# ESP32-S31 register map
Vendor: ESPRESSIF SYSTEMS (SHANGHAI) CO., LTD.; Series: ESP32 S-Series; File version: 1
CPU: RV32IMAFC r0p0, little endian, no MPU, FPU, 0 interrupt priority bits
Address unit: 32 bits
Registers are 32-bit, read-write, reset 0x0 unless marked. A register's access mark holds for its fields unless they carry their own. Offsets are from the block's base; [hi:lo] are bit positions; {n}, {i} and the like mark numbered series.

## SOC_ETM (part 2 of 4) — Event Task Matrix
Base 0x20393000
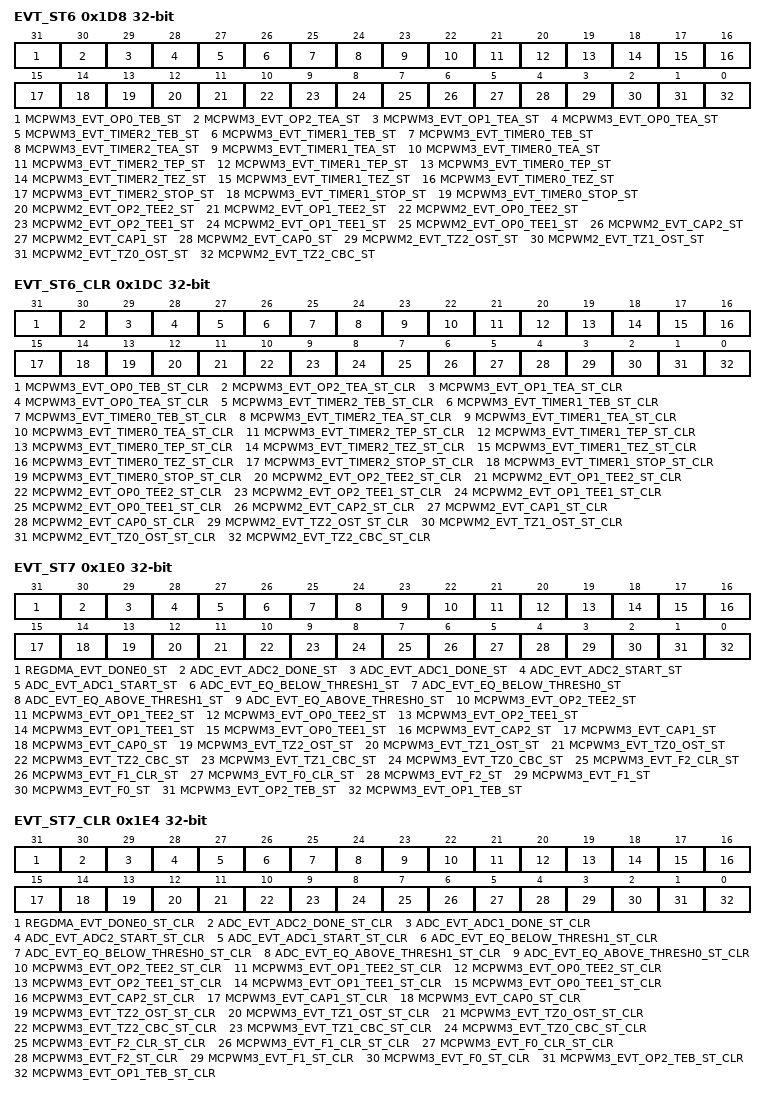
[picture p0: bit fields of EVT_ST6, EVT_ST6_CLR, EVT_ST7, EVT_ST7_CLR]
0x1D8 EVT_ST6 — Events trigger status register
  [31] MCPWM3_EVT_OP0_TEB_ST — Represents MCPWM3_evt_op0_teb trigger status.\\0: Not triggered\\1: Triggered
  [30] MCPWM3_EVT_OP2_TEA_ST — Represents MCPWM3_evt_op2_tea trigger status.\\0: Not triggered\\1: Triggered
  [29] MCPWM3_EVT_OP1_TEA_ST — Represents MCPWM3_evt_op1_tea trigger status.\\0: Not triggered\\1: Triggered
  [28] MCPWM3_EVT_OP0_TEA_ST — Represents MCPWM3_evt_op0_tea trigger status.\\0: Not triggered\\1: Triggered
  [27] MCPWM3_EVT_TIMER2_TEB_ST — Represents MCPWM3_evt_timer2_teb trigger status.\\0: Not triggered\\1: Triggered
  [26] MCPWM3_EVT_TIMER1_TEB_ST — Represents MCPWM3_evt_timer1_teb trigger status.\\0: Not triggered\\1: Triggered
  [25] MCPWM3_EVT_TIMER0_TEB_ST — Represents MCPWM3_evt_timer0_teb trigger status.\\0: Not triggered\\1: Triggered
  [24] MCPWM3_EVT_TIMER2_TEA_ST — Represents MCPWM3_evt_timer2_tea trigger status.\\0: Not triggered\\1: Triggered
  [23] MCPWM3_EVT_TIMER1_TEA_ST — Represents MCPWM3_evt_timer1_tea trigger status.\\0: Not triggered\\1: Triggered
  [22] MCPWM3_EVT_TIMER0_TEA_ST — Represents MCPWM3_evt_timer0_tea trigger status.\\0: Not triggered\\1: Triggered
  [21] MCPWM3_EVT_TIMER2_TEP_ST — Represents MCPWM3_evt_timer2_tep trigger status.\\0: Not triggered\\1: Triggered
  [20] MCPWM3_EVT_TIMER1_TEP_ST — Represents MCPWM3_evt_timer1_tep trigger status.\\0: Not triggered\\1: Triggered
  [19] MCPWM3_EVT_TIMER0_TEP_ST — Represents MCPWM3_evt_timer0_tep trigger status.\\0: Not triggered\\1: Triggered
  [18] MCPWM3_EVT_TIMER2_TEZ_ST — Represents MCPWM3_evt_timer2_tez trigger status.\\0: Not triggered\\1: Triggered
  [17] MCPWM3_EVT_TIMER1_TEZ_ST — Represents MCPWM3_evt_timer1_tez trigger status.\\0: Not triggered\\1: Triggered
  [16] MCPWM3_EVT_TIMER0_TEZ_ST — Represents MCPWM3_evt_timer0_tez trigger status.\\0: Not triggered\\1: Triggered
  [15] MCPWM3_EVT_TIMER2_STOP_ST — Represents MCPWM3_evt_timer2_stop trigger status.\\0: Not triggered\\1: Triggered
  [14] MCPWM3_EVT_TIMER1_STOP_ST — Represents MCPWM3_evt_timer1_stop trigger status.\\0: Not triggered\\1: Triggered
  [13] MCPWM3_EVT_TIMER0_STOP_ST — Represents MCPWM3_evt_timer0_stop trigger status.\\0: Not triggered\\1: Triggered
  [12] MCPWM2_EVT_OP2_TEE2_ST — Represents MCPWM2_evt_op2_tee2 trigger status.\\0: Not triggered\\1: Triggered
  [11] MCPWM2_EVT_OP1_TEE2_ST — Represents MCPWM2_evt_op1_tee2 trigger status.\\0: Not triggered\\1: Triggered
  [10] MCPWM2_EVT_OP0_TEE2_ST — Represents MCPWM2_evt_op0_tee2 trigger status.\\0: Not triggered\\1: Triggered
  [9] MCPWM2_EVT_OP2_TEE1_ST — Represents MCPWM2_evt_op2_tee1 trigger status.\\0: Not triggered\\1: Triggered
  [8] MCPWM2_EVT_OP1_TEE1_ST — Represents MCPWM2_evt_op1_tee1 trigger status.\\0: Not triggered\\1: Triggered
  [7] MCPWM2_EVT_OP0_TEE1_ST — Represents MCPWM2_evt_op0_tee1 trigger status.\\0: Not triggered\\1: Triggered
  [6] MCPWM2_EVT_CAP2_ST — Represents MCPWM2_evt_cap2 trigger status.\\0: Not triggered\\1: Triggered
  [5] MCPWM2_EVT_CAP1_ST — Represents MCPWM2_evt_cap1 trigger status.\\0: Not triggered\\1: Triggered
  [4] MCPWM2_EVT_CAP0_ST — Represents MCPWM2_evt_cap0 trigger status.\\0: Not triggered\\1: Triggered
  [3] MCPWM2_EVT_TZ2_OST_ST — Represents MCPWM2_evt_tz2_ost trigger status.\\0: Not triggered\\1: Triggered
  [2] MCPWM2_EVT_TZ1_OST_ST — Represents MCPWM2_evt_tz1_ost trigger status.\\0: Not triggered\\1: Triggered
  [1] MCPWM2_EVT_TZ0_OST_ST — Represents MCPWM2_evt_tz0_ost trigger status.\\0: Not triggered\\1: Triggered
  [0] MCPWM2_EVT_TZ2_CBC_ST — Represents MCPWM2_evt_tz2_cbc trigger status.\\0: Not triggered\\1: Triggered
0x1DC EVT_ST6_CLR wo — Events trigger status clear register
  [31] MCPWM3_EVT_OP0_TEB_ST_CLR — Configures whether or not to clear MCPWM3_evt_op0_teb trigger status.\\0: Invalid, No effect\\1: Clear
  [30] MCPWM3_EVT_OP2_TEA_ST_CLR — Configures whether or not to clear MCPWM3_evt_op2_tea trigger status.\\0: Invalid, No effect\\1: Clear
  [29] MCPWM3_EVT_OP1_TEA_ST_CLR — Configures whether or not to clear MCPWM3_evt_op1_tea trigger status.\\0: Invalid, No effect\\1: Clear
  [28] MCPWM3_EVT_OP0_TEA_ST_CLR — Configures whether or not to clear MCPWM3_evt_op0_tea trigger status.\\0: Invalid, No effect\\1: Clear
  [27] MCPWM3_EVT_TIMER2_TEB_ST_CLR — Configures whether or not to clear MCPWM3_evt_timer2_teb trigger status.\\0: Invalid, No effect\\1: Clear
  [26] MCPWM3_EVT_TIMER1_TEB_ST_CLR — Configures whether or not to clear MCPWM3_evt_timer1_teb trigger status.\\0: Invalid, No effect\\1: Clear
  [25] MCPWM3_EVT_TIMER0_TEB_ST_CLR — Configures whether or not to clear MCPWM3_evt_timer0_teb trigger status.\\0: Invalid, No effect\\1: Clear
  [24] MCPWM3_EVT_TIMER2_TEA_ST_CLR — Configures whether or not to clear MCPWM3_evt_timer2_tea trigger status.\\0: Invalid, No effect\\1: Clear
  [23] MCPWM3_EVT_TIMER1_TEA_ST_CLR — Configures whether or not to clear MCPWM3_evt_timer1_tea trigger status.\\0: Invalid, No effect\\1: Clear
  [22] MCPWM3_EVT_TIMER0_TEA_ST_CLR — Configures whether or not to clear MCPWM3_evt_timer0_tea trigger status.\\0: Invalid, No effect\\1: Clear
  [21] MCPWM3_EVT_TIMER2_TEP_ST_CLR — Configures whether or not to clear MCPWM3_evt_timer2_tep trigger status.\\0: Invalid, No effect\\1: Clear
  [20] MCPWM3_EVT_TIMER1_TEP_ST_CLR — Configures whether or not to clear MCPWM3_evt_timer1_tep trigger status.\\0: Invalid, No effect\\1: Clear
  [19] MCPWM3_EVT_TIMER0_TEP_ST_CLR — Configures whether or not to clear MCPWM3_evt_timer0_tep trigger status.\\0: Invalid, No effect\\1: Clear
  [18] MCPWM3_EVT_TIMER2_TEZ_ST_CLR — Configures whether or not to clear MCPWM3_evt_timer2_tez trigger status.\\0: Invalid, No effect\\1: Clear
  [17] MCPWM3_EVT_TIMER1_TEZ_ST_CLR — Configures whether or not to clear MCPWM3_evt_timer1_tez trigger status.\\0: Invalid, No effect\\1: Clear
  [16] MCPWM3_EVT_TIMER0_TEZ_ST_CLR — Configures whether or not to clear MCPWM3_evt_timer0_tez trigger status.\\0: Invalid, No effect\\1: Clear
  [15] MCPWM3_EVT_TIMER2_STOP_ST_CLR — Configures whether or not to clear MCPWM3_evt_timer2_stop trigger status.\\0: Invalid, No effect\\1: Clear
  [14] MCPWM3_EVT_TIMER1_STOP_ST_CLR — Configures whether or not to clear MCPWM3_evt_timer1_stop trigger status.\\0: Invalid, No effect\\1: Clear
  [13] MCPWM3_EVT_TIMER0_STOP_ST_CLR — Configures whether or not to clear MCPWM3_evt_timer0_stop trigger status.\\0: Invalid, No effect\\1: Clear
  [12] MCPWM2_EVT_OP2_TEE2_ST_CLR — Configures whether or not to clear MCPWM2_evt_op2_tee2 trigger status.\\0: Invalid, No effect\\1: Clear
  [11] MCPWM2_EVT_OP1_TEE2_ST_CLR — Configures whether or not to clear MCPWM2_evt_op1_tee2 trigger status.\\0: Invalid, No effect\\1: Clear
  [10] MCPWM2_EVT_OP0_TEE2_ST_CLR — Configures whether or not to clear MCPWM2_evt_op0_tee2 trigger status.\\0: Invalid, No effect\\1: Clear
  [9] MCPWM2_EVT_OP2_TEE1_ST_CLR — Configures whether or not to clear MCPWM2_evt_op2_tee1 trigger status.\\0: Invalid, No effect\\1: Clear
  [8] MCPWM2_EVT_OP1_TEE1_ST_CLR — Configures whether or not to clear MCPWM2_evt_op1_tee1 trigger status.\\0: Invalid, No effect\\1: Clear
  [7] MCPWM2_EVT_OP0_TEE1_ST_CLR — Configures whether or not to clear MCPWM2_evt_op0_tee1 trigger status.\\0: Invalid, No effect\\1: Clear
  [6] MCPWM2_EVT_CAP2_ST_CLR — Configures whether or not to clear MCPWM2_evt_cap2 trigger status.\\0: Invalid, No effect\\1: Clear
  [5] MCPWM2_EVT_CAP1_ST_CLR — Configures whether or not to clear MCPWM2_evt_cap1 trigger status.\\0: Invalid, No effect\\1: Clear
  [4] MCPWM2_EVT_CAP0_ST_CLR — Configures whether or not to clear MCPWM2_evt_cap0 trigger status.\\0: Invalid, No effect\\1: Clear
  [3] MCPWM2_EVT_TZ2_OST_ST_CLR — Configures whether or not to clear MCPWM2_evt_tz2_ost trigger status.\\0: Invalid, No effect\\1: Clear
  [2] MCPWM2_EVT_TZ1_OST_ST_CLR — Configures whether or not to clear MCPWM2_evt_tz1_ost trigger status.\\0: Invalid, No effect\\1: Clear
  [1] MCPWM2_EVT_TZ0_OST_ST_CLR — Configures whether or not to clear MCPWM2_evt_tz0_ost trigger status.\\0: Invalid, No effect\\1: Clear
  [0] MCPWM2_EVT_TZ2_CBC_ST_CLR — Configures whether or not to clear MCPWM2_evt_tz2_cbc trigger status.\\0: Invalid, No effect\\1: Clear
0x1E0 EVT_ST7 — Events trigger status register
  [31] REGDMA_EVT_DONE0_ST — Represents REGDMA_evt_done0 trigger status.\\0: Not triggered\\1: Triggered
  [30] ADC_EVT_ADC2_DONE_ST — Represents ADC_evt_adc2_done trigger status.\\0: Not triggered\\1: Triggered
  [29] ADC_EVT_ADC1_DONE_ST — Represents ADC_evt_adc1_done trigger status.\\0: Not triggered\\1: Triggered
  [28] ADC_EVT_ADC2_START_ST — Represents ADC_evt_adc2_start trigger status.\\0: Not triggered\\1: Triggered
  [27] ADC_EVT_ADC1_START_ST — Represents ADC_evt_adc1_start trigger status.\\0: Not triggered\\1: Triggered
  [26] ADC_EVT_EQ_BELOW_THRESH1_ST — Represents ADC_evt_eq_below_thresh1 trigger status.\\0: Not triggered\\1: Triggered
  [25] ADC_EVT_EQ_BELOW_THRESH0_ST — Represents ADC_evt_eq_below_thresh0 trigger status.\\0: Not triggered\\1: Triggered
  [24] ADC_EVT_EQ_ABOVE_THRESH1_ST — Represents ADC_evt_eq_above_thresh1 trigger status.\\0: Not triggered\\1: Triggered
  [23] ADC_EVT_EQ_ABOVE_THRESH0_ST — Represents ADC_evt_eq_above_thresh0 trigger status.\\0: Not triggered\\1: Triggered
  [22] MCPWM3_EVT_OP2_TEE2_ST — Represents MCPWM3_evt_op2_tee2 trigger status.\\0: Not triggered\\1: Triggered
  [21] MCPWM3_EVT_OP1_TEE2_ST — Represents MCPWM3_evt_op1_tee2 trigger status.\\0: Not triggered\\1: Triggered
  [20] MCPWM3_EVT_OP0_TEE2_ST — Represents MCPWM3_evt_op0_tee2 trigger status.\\0: Not triggered\\1: Triggered
  [19] MCPWM3_EVT_OP2_TEE1_ST — Represents MCPWM3_evt_op2_tee1 trigger status.\\0: Not triggered\\1: Triggered
  [18] MCPWM3_EVT_OP1_TEE1_ST — Represents MCPWM3_evt_op1_tee1 trigger status.\\0: Not triggered\\1: Triggered
  [17] MCPWM3_EVT_OP0_TEE1_ST — Represents MCPWM3_evt_op0_tee1 trigger status.\\0: Not triggered\\1: Triggered
  [16] MCPWM3_EVT_CAP2_ST — Represents MCPWM3_evt_cap2 trigger status.\\0: Not triggered\\1: Triggered
  [15] MCPWM3_EVT_CAP1_ST — Represents MCPWM3_evt_cap1 trigger status.\\0: Not triggered\\1: Triggered
  [14] MCPWM3_EVT_CAP0_ST — Represents MCPWM3_evt_cap0 trigger status.\\0: Not triggered\\1: Triggered
  [13] MCPWM3_EVT_TZ2_OST_ST — Represents MCPWM3_evt_tz2_ost trigger status.\\0: Not triggered\\1: Triggered
  [12] MCPWM3_EVT_TZ1_OST_ST — Represents MCPWM3_evt_tz1_ost trigger status.\\0: Not triggered\\1: Triggered
  [11] MCPWM3_EVT_TZ0_OST_ST — Represents MCPWM3_evt_tz0_ost trigger status.\\0: Not triggered\\1: Triggered
  [10] MCPWM3_EVT_TZ2_CBC_ST — Represents MCPWM3_evt_tz2_cbc trigger status.\\0: Not triggered\\1: Triggered
  [9] MCPWM3_EVT_TZ1_CBC_ST — Represents MCPWM3_evt_tz1_cbc trigger status.\\0: Not triggered\\1: Triggered
  [8] MCPWM3_EVT_TZ0_CBC_ST — Represents MCPWM3_evt_tz0_cbc trigger status.\\0: Not triggered\\1: Triggered
  [7] MCPWM3_EVT_F2_CLR_ST — Represents MCPWM3_evt_f2_clr trigger status.\\0: Not triggered\\1: Triggered
  [6] MCPWM3_EVT_F1_CLR_ST — Represents MCPWM3_evt_f1_clr trigger status.\\0: Not triggered\\1: Triggered
  [5] MCPWM3_EVT_F0_CLR_ST — Represents MCPWM3_evt_f0_clr trigger status.\\0: Not triggered\\1: Triggered
  [4] MCPWM3_EVT_F2_ST — Represents MCPWM3_evt_f2 trigger status.\\0: Not triggered\\1: Triggered
  [3] MCPWM3_EVT_F1_ST — Represents MCPWM3_evt_f1 trigger status.\\0: Not triggered\\1: Triggered
  [2] MCPWM3_EVT_F0_ST — Represents MCPWM3_evt_f0 trigger status.\\0: Not triggered\\1: Triggered
  [1] MCPWM3_EVT_OP2_TEB_ST — Represents MCPWM3_evt_op2_teb trigger status.\\0: Not triggered\\1: Triggered
  [0] MCPWM3_EVT_OP1_TEB_ST — Represents MCPWM3_evt_op1_teb trigger status.\\0: Not triggered\\1: Triggered
0x1E4 EVT_ST7_CLR wo — Events trigger status clear register
  [31] REGDMA_EVT_DONE0_ST_CLR — Configures whether or not to clear REGDMA_evt_done0 trigger status.\\0: Invalid, No effect\\1: Clear
  [30] ADC_EVT_ADC2_DONE_ST_CLR — Configures whether or not to clear ADC_evt_adc2_done trigger status.\\0: Invalid, No effect\\1: Clear
  [29] ADC_EVT_ADC1_DONE_ST_CLR — Configures whether or not to clear ADC_evt_adc1_done trigger status.\\0: Invalid, No effect\\1: Clear
  [28] ADC_EVT_ADC2_START_ST_CLR — Configures whether or not to clear ADC_evt_adc2_start trigger status.\\0: Invalid, No effect\\1: Clear
  [27] ADC_EVT_ADC1_START_ST_CLR — Configures whether or not to clear ADC_evt_adc1_start trigger status.\\0: Invalid, No effect\\1: Clear
  [26] ADC_EVT_EQ_BELOW_THRESH1_ST_CLR — Configures whether or not to clear ADC_evt_eq_below_thresh1 trigger status.\\0: Invalid, No effect\\1: Clear
  [25] ADC_EVT_EQ_BELOW_THRESH0_ST_CLR — Configures whether or not to clear ADC_evt_eq_below_thresh0 trigger status.\\0: Invalid, No effect\\1: Clear
  [24] ADC_EVT_EQ_ABOVE_THRESH1_ST_CLR — Configures whether or not to clear ADC_evt_eq_above_thresh1 trigger status.\\0: Invalid, No effect\\1: Clear
  [23] ADC_EVT_EQ_ABOVE_THRESH0_ST_CLR — Configures whether or not to clear ADC_evt_eq_above_thresh0 trigger status.\\0: Invalid, No effect\\1: Clear
  [22] MCPWM3_EVT_OP2_TEE2_ST_CLR — Configures whether or not to clear MCPWM3_evt_op2_tee2 trigger status.\\0: Invalid, No effect\\1: Clear
  [21] MCPWM3_EVT_OP1_TEE2_ST_CLR — Configures whether or not to clear MCPWM3_evt_op1_tee2 trigger status.\\0: Invalid, No effect\\1: Clear
  [20] MCPWM3_EVT_OP0_TEE2_ST_CLR — Configures whether or not to clear MCPWM3_evt_op0_tee2 trigger status.\\0: Invalid, No effect\\1: Clear
  [19] MCPWM3_EVT_OP2_TEE1_ST_CLR — Configures whether or not to clear MCPWM3_evt_op2_tee1 trigger status.\\0: Invalid, No effect\\1: Clear
  [18] MCPWM3_EVT_OP1_TEE1_ST_CLR — Configures whether or not to clear MCPWM3_evt_op1_tee1 trigger status.\\0: Invalid, No effect\\1: Clear
  [17] MCPWM3_EVT_OP0_TEE1_ST_CLR — Configures whether or not to clear MCPWM3_evt_op0_tee1 trigger status.\\0: Invalid, No effect\\1: Clear
  [16] MCPWM3_EVT_CAP2_ST_CLR — Configures whether or not to clear MCPWM3_evt_cap2 trigger status.\\0: Invalid, No effect\\1: Clear
  [15] MCPWM3_EVT_CAP1_ST_CLR — Configures whether or not to clear MCPWM3_evt_cap1 trigger status.\\0: Invalid, No effect\\1: Clear
  [14] MCPWM3_EVT_CAP0_ST_CLR — Configures whether or not to clear MCPWM3_evt_cap0 trigger status.\\0: Invalid, No effect\\1: Clear
  [13] MCPWM3_EVT_TZ2_OST_ST_CLR — Configures whether or not to clear MCPWM3_evt_tz2_ost trigger status.\\0: Invalid, No effect\\1: Clear
  [12] MCPWM3_EVT_TZ1_OST_ST_CLR — Configures whether or not to clear MCPWM3_evt_tz1_ost trigger status.\\0: Invalid, No effect\\1: Clear
  [11] MCPWM3_EVT_TZ0_OST_ST_CLR — Configures whether or not to clear MCPWM3_evt_tz0_ost trigger status.\\0: Invalid, No effect\\1: Clear
  [10] MCPWM3_EVT_TZ2_CBC_ST_CLR — Configures whether or not to clear MCPWM3_evt_tz2_cbc trigger status.\\0: Invalid, No effect\\1: Clear
  [9] MCPWM3_EVT_TZ1_CBC_ST_CLR — Configures whether or not to clear MCPWM3_evt_tz1_cbc trigger status.\\0: Invalid, No effect\\1: Clear
  [8] MCPWM3_EVT_TZ0_CBC_ST_CLR — Configures whether or not to clear MCPWM3_evt_tz0_cbc trigger status.\\0: Invalid, No effect\\1: Clear
  [7] MCPWM3_EVT_F2_CLR_ST_CLR — Configures whether or not to clear MCPWM3_evt_f2_clr trigger status.\\0: Invalid, No effect\\1: Clear
  [6] MCPWM3_EVT_F1_CLR_ST_CLR — Configures whether or not to clear MCPWM3_evt_f1_clr trigger status.\\0: Invalid, No effect\\1: Clear
  [5] MCPWM3_EVT_F0_CLR_ST_CLR — Configures whether or not to clear MCPWM3_evt_f0_clr trigger status.\\0: Invalid, No effect\\1: Clear
  [4] MCPWM3_EVT_F2_ST_CLR — Configures whether or not to clear MCPWM3_evt_f2 trigger status.\\0: Invalid, No effect\\1: Clear
  [3] MCPWM3_EVT_F1_ST_CLR — Configures whether or not to clear MCPWM3_evt_f1 trigger status.\\0: Invalid, No effect\\1: Clear
  [2] MCPWM3_EVT_F0_ST_CLR — Configures whether or not to clear MCPWM3_evt_f0 trigger status.\\0: Invalid, No effect\\1: Clear
  [1] MCPWM3_EVT_OP2_TEB_ST_CLR — Configures whether or not to clear MCPWM3_evt_op2_teb trigger status.\\0: Invalid, No effect\\1: Clear
  [0] MCPWM3_EVT_OP1_TEB_ST_CLR — Configures whether or not to clear MCPWM3_evt_op1_teb trigger status.\\0: Invalid, No effect\\1: Clear
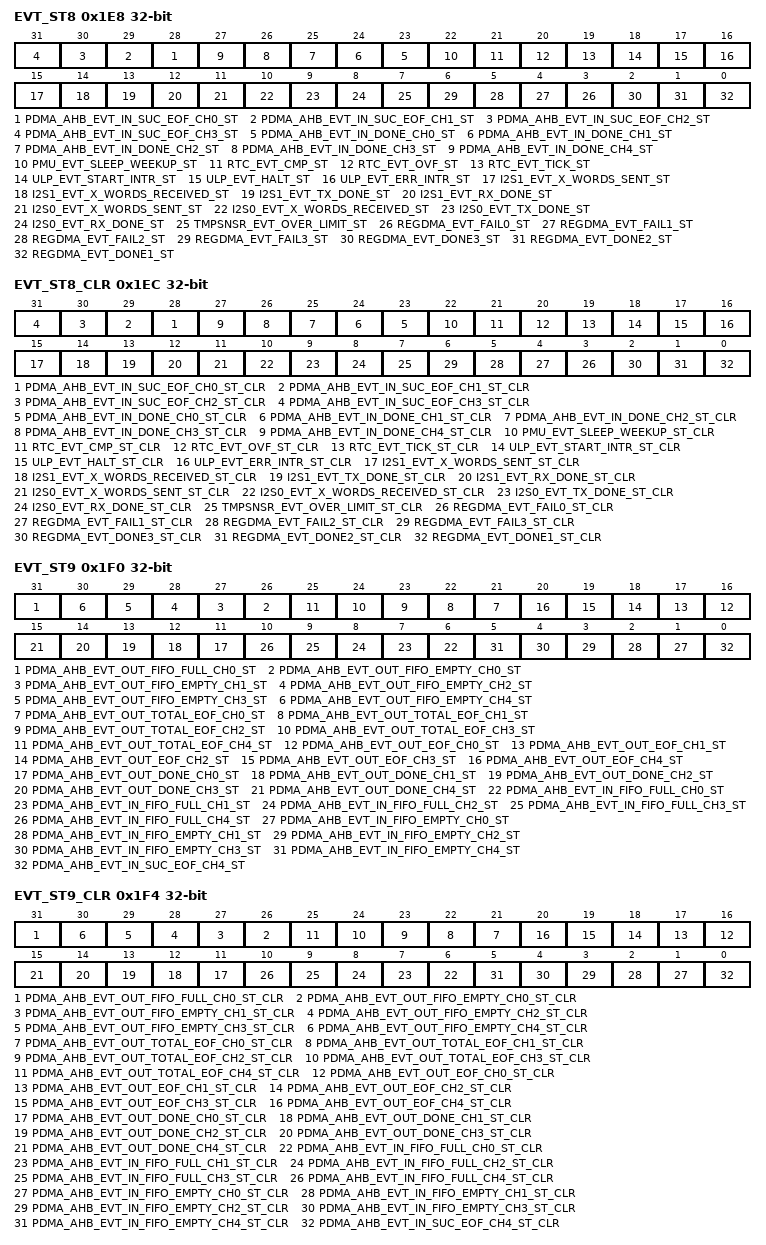
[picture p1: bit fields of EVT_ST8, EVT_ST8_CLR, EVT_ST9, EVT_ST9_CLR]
0x1E8 EVT_ST8 — Events trigger status register
  [n+28] PDMA_AHB_EVT_IN_SUC_EOF_CH{n}_ST (n=0..3) — Represents PDMA_AHB_evt_in_suc_eof_ch{n} trigger status.\\0: Not triggered\\1: Triggered
  [n+23] PDMA_AHB_EVT_IN_DONE_CH{n}_ST (n=0..4) — Represents PDMA_AHB_evt_in_done_ch{n} trigger status.\\0: Not triggered\\1: Triggered
  [22] PMU_EVT_SLEEP_WEEKUP_ST — Represents PMU_evt_sleep_weekup trigger status.\\0: Not triggered\\1: Triggered
  [21] RTC_EVT_CMP_ST — Represents RTC_evt_cmp trigger status.\\0: Not triggered\\1: Triggered
  [20] RTC_EVT_OVF_ST — Represents RTC_evt_ovf trigger status.\\0: Not triggered\\1: Triggered
  [19] RTC_EVT_TICK_ST — Represents RTC_evt_tick trigger status.\\0: Not triggered\\1: Triggered
  [18] ULP_EVT_START_INTR_ST — Represents ULP_evt_start_intr trigger status.\\0: Not triggered\\1: Triggered
  [17] ULP_EVT_HALT_ST — Represents ULP_evt_halt trigger status.\\0: Not triggered\\1: Triggered
  [16] ULP_EVT_ERR_INTR_ST — Represents ULP_evt_err_intr trigger status.\\0: Not triggered\\1: Triggered
  [15] I2S1_EVT_X_WORDS_SENT_ST — Represents I2S1_evt_x_words_sent trigger status.\\0: Not triggered\\1: Triggered
  [14] I2S1_EVT_X_WORDS_RECEIVED_ST — Represents I2S1_evt_x_words_received trigger status.\\0: Not triggered\\1: Triggered
  [13] I2S1_EVT_TX_DONE_ST — Represents I2S1_evt_tx_done trigger status.\\0: Not triggered\\1: Triggered
  [12] I2S1_EVT_RX_DONE_ST — Represents I2S1_evt_rx_done trigger status.\\0: Not triggered\\1: Triggered
  [11] I2S0_EVT_X_WORDS_SENT_ST — Represents I2S0_evt_x_words_sent trigger status.\\0: Not triggered\\1: Triggered
  [10] I2S0_EVT_X_WORDS_RECEIVED_ST — Represents I2S0_evt_x_words_received trigger status.\\0: Not triggered\\1: Triggered
  [9] I2S0_EVT_TX_DONE_ST — Represents I2S0_evt_tx_done trigger status.\\0: Not triggered\\1: Triggered
  [8] I2S0_EVT_RX_DONE_ST — Represents I2S0_evt_rx_done trigger status.\\0: Not triggered\\1: Triggered
  [7] TMPSNSR_EVT_OVER_LIMIT_ST — Represents TMPSNSR_evt_over_limit trigger status.\\0: Not triggered\\1: Triggered
  [n+3] REGDMA_EVT_FAIL{n}_ST (n=0..3) — Represents REGDMA_evt_fail{n} trigger status.\\0: Not triggered\\1: Triggered
  [2] REGDMA_EVT_DONE3_ST — Represents REGDMA_evt_done3 trigger status.\\0: Not triggered\\1: Triggered
  [1] REGDMA_EVT_DONE2_ST — Represents REGDMA_evt_done2 trigger status.\\0: Not triggered\\1: Triggered
  [0] REGDMA_EVT_DONE1_ST — Represents REGDMA_evt_done1 trigger status.\\0: Not triggered\\1: Triggered
0x1EC EVT_ST8_CLR wo — Events trigger status clear register
  [n+28] PDMA_AHB_EVT_IN_SUC_EOF_CH{n}_ST_CLR (n=0..3) — Configures whether or not to clear PDMA_AHB_evt_in_suc_eof_ch{n} trigger status.\\0: Invalid, No effect\\1: Clear
  [n+23] PDMA_AHB_EVT_IN_DONE_CH{n}_ST_CLR (n=0..4) — Configures whether or not to clear PDMA_AHB_evt_in_done_ch{n} trigger status.\\0: Invalid, No effect\\1: Clear
  [22] PMU_EVT_SLEEP_WEEKUP_ST_CLR — Configures whether or not to clear PMU_evt_sleep_weekup trigger status.\\0: Invalid, No effect\\1: Clear
  [21] RTC_EVT_CMP_ST_CLR — Configures whether or not to clear RTC_evt_cmp trigger status.\\0: Invalid, No effect\\1: Clear
  [20] RTC_EVT_OVF_ST_CLR — Configures whether or not to clear RTC_evt_ovf trigger status.\\0: Invalid, No effect\\1: Clear
  [19] RTC_EVT_TICK_ST_CLR — Configures whether or not to clear RTC_evt_tick trigger status.\\0: Invalid, No effect\\1: Clear
  [18] ULP_EVT_START_INTR_ST_CLR — Configures whether or not to clear ULP_evt_start_intr trigger status.\\0: Invalid, No effect\\1: Clear
  [17] ULP_EVT_HALT_ST_CLR — Configures whether or not to clear ULP_evt_halt trigger status.\\0: Invalid, No effect\\1: Clear
  [16] ULP_EVT_ERR_INTR_ST_CLR — Configures whether or not to clear ULP_evt_err_intr trigger status.\\0: Invalid, No effect\\1: Clear
  [15] I2S1_EVT_X_WORDS_SENT_ST_CLR — Configures whether or not to clear I2S1_evt_x_words_sent trigger status.\\0: Invalid, No effect\\1: Clear
  [14] I2S1_EVT_X_WORDS_RECEIVED_ST_CLR — Configures whether or not to clear I2S1_evt_x_words_received trigger status.\\0: Invalid, No effect\\1: Clear
  [13] I2S1_EVT_TX_DONE_ST_CLR — Configures whether or not to clear I2S1_evt_tx_done trigger status.\\0: Invalid, No effect\\1: Clear
  [12] I2S1_EVT_RX_DONE_ST_CLR — Configures whether or not to clear I2S1_evt_rx_done trigger status.\\0: Invalid, No effect\\1: Clear
  [11] I2S0_EVT_X_WORDS_SENT_ST_CLR — Configures whether or not to clear I2S0_evt_x_words_sent trigger status.\\0: Invalid, No effect\\1: Clear
  [10] I2S0_EVT_X_WORDS_RECEIVED_ST_CLR — Configures whether or not to clear I2S0_evt_x_words_received trigger status.\\0: Invalid, No effect\\1: Clear
  [9] I2S0_EVT_TX_DONE_ST_CLR — Configures whether or not to clear I2S0_evt_tx_done trigger status.\\0: Invalid, No effect\\1: Clear
  [8] I2S0_EVT_RX_DONE_ST_CLR — Configures whether or not to clear I2S0_evt_rx_done trigger status.\\0: Invalid, No effect\\1: Clear
  [7] TMPSNSR_EVT_OVER_LIMIT_ST_CLR — Configures whether or not to clear TMPSNSR_evt_over_limit trigger status.\\0: Invalid, No effect\\1: Clear
  [n+3] REGDMA_EVT_FAIL{n}_ST_CLR (n=0..3) — Configures whether or not to clear REGDMA_evt_fail{n} trigger status.\\0: Invalid, No effect\\1: Clear
  [2] REGDMA_EVT_DONE3_ST_CLR — Configures whether or not to clear REGDMA_evt_done3 trigger status.\\0: Invalid, No effect\\1: Clear
  [1] REGDMA_EVT_DONE2_ST_CLR — Configures whether or not to clear REGDMA_evt_done2 trigger status.\\0: Invalid, No effect\\1: Clear
  [0] REGDMA_EVT_DONE1_ST_CLR — Configures whether or not to clear REGDMA_evt_done1 trigger status.\\0: Invalid, No effect\\1: Clear
0x1F0 EVT_ST9 — Events trigger status register
  [31] PDMA_AHB_EVT_OUT_FIFO_FULL_CH0_ST — Represents PDMA_AHB_evt_out_fifo_full_ch0 trigger status.\\0: Not triggered\\1: Triggered
  [n+26] PDMA_AHB_EVT_OUT_FIFO_EMPTY_CH{n}_ST (n=0..4) — Represents PDMA_AHB_evt_out_fifo_empty_ch{n} trigger status.\\0: Not triggered\\1: Triggered
  [n+21] PDMA_AHB_EVT_OUT_TOTAL_EOF_CH{n}_ST (n=0..4) — Represents PDMA_AHB_evt_out_total_eof_ch{n} trigger status.\\0: Not triggered\\1: Triggered
  [n+16] PDMA_AHB_EVT_OUT_EOF_CH{n}_ST (n=0..4) — Represents PDMA_AHB_evt_out_eof_ch{n} trigger status.\\0: Not triggered\\1: Triggered
  [n+11] PDMA_AHB_EVT_OUT_DONE_CH{n}_ST (n=0..4) — Represents PDMA_AHB_evt_out_done_ch{n} trigger status.\\0: Not triggered\\1: Triggered
  [n+6] PDMA_AHB_EVT_IN_FIFO_FULL_CH{n}_ST (n=0..4) — Represents PDMA_AHB_evt_in_fifo_full_ch{n} trigger status.\\0: Not triggered\\1: Triggered
  [n+1] PDMA_AHB_EVT_IN_FIFO_EMPTY_CH{n}_ST (n=0..4) — Represents PDMA_AHB_evt_in_fifo_empty_ch{n} trigger status.\\0: Not triggered\\1: Triggered
  [0] PDMA_AHB_EVT_IN_SUC_EOF_CH4_ST — Represents PDMA_AHB_evt_in_suc_eof_ch4 trigger status.\\0: Not triggered\\1: Triggered
0x1F4 EVT_ST9_CLR wo — Events trigger status clear register
  [31] PDMA_AHB_EVT_OUT_FIFO_FULL_CH0_ST_CLR — Configures whether or not to clear PDMA_AHB_evt_out_fifo_full_ch0 trigger status.\\0: Invalid, No effect\\1: Clear
  [n+26] PDMA_AHB_EVT_OUT_FIFO_EMPTY_CH{n}_ST_CLR (n=0..4) — Configures whether or not to clear PDMA_AHB_evt_out_fifo_empty_ch{n} trigger status.\\0: Invalid, No effect\\1: Clear
  [n+21] PDMA_AHB_EVT_OUT_TOTAL_EOF_CH{n}_ST_CLR (n=0..4) — Configures whether or not to clear PDMA_AHB_evt_out_total_eof_ch{n} trigger status.\\0: Invalid, No effect\\1: Clear
  [n+16] PDMA_AHB_EVT_OUT_EOF_CH{n}_ST_CLR (n=0..4) — Configures whether or not to clear PDMA_AHB_evt_out_eof_ch{n} trigger status.\\0: Invalid, No effect\\1: Clear
  [n+11] PDMA_AHB_EVT_OUT_DONE_CH{n}_ST_CLR (n=0..4) — Configures whether or not to clear PDMA_AHB_evt_out_done_ch{n} trigger status.\\0: Invalid, No effect\\1: Clear
  [n+6] PDMA_AHB_EVT_IN_FIFO_FULL_CH{n}_ST_CLR (n=0..4) — Configures whether or not to clear PDMA_AHB_evt_in_fifo_full_ch{n} trigger status.\\0: Invalid, No effect\\1: Clear
  [n+1] PDMA_AHB_EVT_IN_FIFO_EMPTY_CH{n}_ST_CLR (n=0..4) — Configures whether or not to clear PDMA_AHB_evt_in_fifo_empty_ch{n} trigger status.\\0: Invalid, No effect\\1: Clear
  [0] PDMA_AHB_EVT_IN_SUC_EOF_CH4_ST_CLR — Configures whether or not to clear PDMA_AHB_evt_in_suc_eof_ch4 trigger status.\\0: Invalid, No effect\\1: Clear
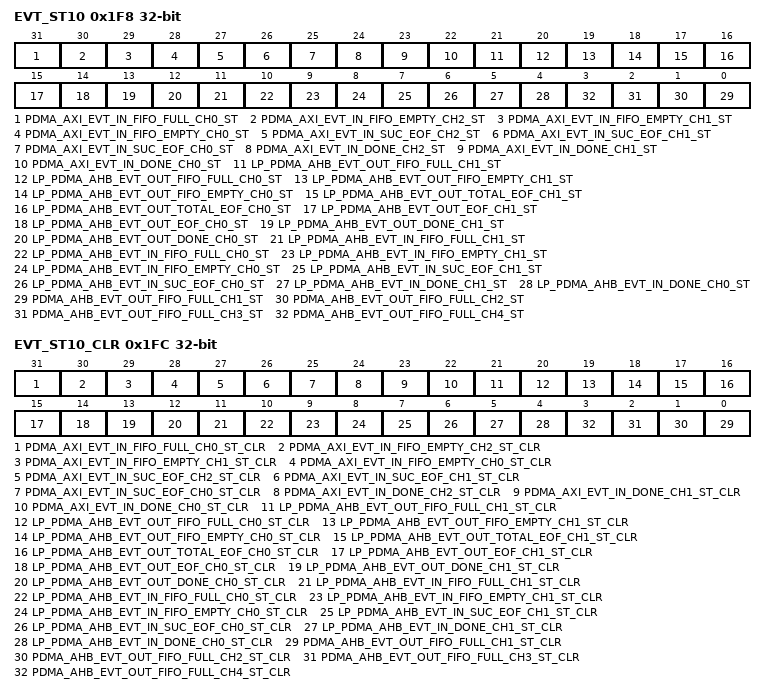
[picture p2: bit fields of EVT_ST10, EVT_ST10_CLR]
0x1F8 EVT_ST10 — Events trigger status register
  [31] PDMA_AXI_EVT_IN_FIFO_FULL_CH0_ST — Represents PDMA_AXI_evt_in_fifo_full_ch0 trigger status.\\0: Not triggered\\1: Triggered
  [30] PDMA_AXI_EVT_IN_FIFO_EMPTY_CH2_ST — Represents PDMA_AXI_evt_in_fifo_empty_ch2 trigger status.\\0: Not triggered\\1: Triggered
  [29] PDMA_AXI_EVT_IN_FIFO_EMPTY_CH1_ST — Represents PDMA_AXI_evt_in_fifo_empty_ch1 trigger status.\\0: Not triggered\\1: Triggered
  [28] PDMA_AXI_EVT_IN_FIFO_EMPTY_CH0_ST — Represents PDMA_AXI_evt_in_fifo_empty_ch0 trigger status.\\0: Not triggered\\1: Triggered
  [27] PDMA_AXI_EVT_IN_SUC_EOF_CH2_ST — Represents PDMA_AXI_evt_in_suc_eof_ch2 trigger status.\\0: Not triggered\\1: Triggered
  [26] PDMA_AXI_EVT_IN_SUC_EOF_CH1_ST — Represents PDMA_AXI_evt_in_suc_eof_ch1 trigger status.\\0: Not triggered\\1: Triggered
  [25] PDMA_AXI_EVT_IN_SUC_EOF_CH0_ST — Represents PDMA_AXI_evt_in_suc_eof_ch0 trigger status.\\0: Not triggered\\1: Triggered
  [24] PDMA_AXI_EVT_IN_DONE_CH2_ST — Represents PDMA_AXI_evt_in_done_ch2 trigger status.\\0: Not triggered\\1: Triggered
  [23] PDMA_AXI_EVT_IN_DONE_CH1_ST — Represents PDMA_AXI_evt_in_done_ch1 trigger status.\\0: Not triggered\\1: Triggered
  [22] PDMA_AXI_EVT_IN_DONE_CH0_ST — Represents PDMA_AXI_evt_in_done_ch0 trigger status.\\0: Not triggered\\1: Triggered
  [21] LP_PDMA_AHB_EVT_OUT_FIFO_FULL_CH1_ST — Represents LP_PDMA_AHB_evt_out_fifo_full_ch1 trigger status.\\0: Not triggered\\1: Triggered
  [20] LP_PDMA_AHB_EVT_OUT_FIFO_FULL_CH0_ST — Represents LP_PDMA_AHB_evt_out_fifo_full_ch0 trigger status.\\0: Not triggered\\1: Triggered
  [19] LP_PDMA_AHB_EVT_OUT_FIFO_EMPTY_CH1_ST — Represents LP_PDMA_AHB_evt_out_fifo_empty_ch1 trigger status.\\0: Not triggered\\1: Triggered
  [18] LP_PDMA_AHB_EVT_OUT_FIFO_EMPTY_CH0_ST — Represents LP_PDMA_AHB_evt_out_fifo_empty_ch0 trigger status.\\0: Not triggered\\1: Triggered
  [17] LP_PDMA_AHB_EVT_OUT_TOTAL_EOF_CH1_ST — Represents LP_PDMA_AHB_evt_out_total_eof_ch1 trigger status.\\0: Not triggered\\1: Triggered
  [16] LP_PDMA_AHB_EVT_OUT_TOTAL_EOF_CH0_ST — Represents LP_PDMA_AHB_evt_out_total_eof_ch0 trigger status.\\0: Not triggered\\1: Triggered
  [15] LP_PDMA_AHB_EVT_OUT_EOF_CH1_ST — Represents LP_PDMA_AHB_evt_out_eof_ch1 trigger status.\\0: Not triggered\\1: Triggered
  [14] LP_PDMA_AHB_EVT_OUT_EOF_CH0_ST — Represents LP_PDMA_AHB_evt_out_eof_ch0 trigger status.\\0: Not triggered\\1: Triggered
  [13] LP_PDMA_AHB_EVT_OUT_DONE_CH1_ST — Represents LP_PDMA_AHB_evt_out_done_ch1 trigger status.\\0: Not triggered\\1: Triggered
  [12] LP_PDMA_AHB_EVT_OUT_DONE_CH0_ST — Represents LP_PDMA_AHB_evt_out_done_ch0 trigger status.\\0: Not triggered\\1: Triggered
  [11] LP_PDMA_AHB_EVT_IN_FIFO_FULL_CH1_ST — Represents LP_PDMA_AHB_evt_in_fifo_full_ch1 trigger status.\\0: Not triggered\\1: Triggered
  [10] LP_PDMA_AHB_EVT_IN_FIFO_FULL_CH0_ST — Represents LP_PDMA_AHB_evt_in_fifo_full_ch0 trigger status.\\0: Not triggered\\1: Triggered
  [9] LP_PDMA_AHB_EVT_IN_FIFO_EMPTY_CH1_ST — Represents LP_PDMA_AHB_evt_in_fifo_empty_ch1 trigger status.\\0: Not triggered\\1: Triggered
  [8] LP_PDMA_AHB_EVT_IN_FIFO_EMPTY_CH0_ST — Represents LP_PDMA_AHB_evt_in_fifo_empty_ch0 trigger status.\\0: Not triggered\\1: Triggered
  [7] LP_PDMA_AHB_EVT_IN_SUC_EOF_CH1_ST — Represents LP_PDMA_AHB_evt_in_suc_eof_ch1 trigger status.\\0: Not triggered\\1: Triggered
  [6] LP_PDMA_AHB_EVT_IN_SUC_EOF_CH0_ST — Represents LP_PDMA_AHB_evt_in_suc_eof_ch0 trigger status.\\0: Not triggered\\1: Triggered
  [5] LP_PDMA_AHB_EVT_IN_DONE_CH1_ST — Represents LP_PDMA_AHB_evt_in_done_ch1 trigger status.\\0: Not triggered\\1: Triggered
  [4] LP_PDMA_AHB_EVT_IN_DONE_CH0_ST — Represents LP_PDMA_AHB_evt_in_done_ch0 trigger status.\\0: Not triggered\\1: Triggered
  [n-1] PDMA_AHB_EVT_OUT_FIFO_FULL_CH{n}_ST (n=1..4) — Represents PDMA_AHB_evt_out_fifo_full_ch{n} trigger status.\\0: Not triggered\\1: Triggered
0x1FC EVT_ST10_CLR wo — Events trigger status clear register
  [31] PDMA_AXI_EVT_IN_FIFO_FULL_CH0_ST_CLR — Configures whether or not to clear PDMA_AXI_evt_in_fifo_full_ch0 trigger status.\\0: Invalid, No effect\\1: Clear
  [30] PDMA_AXI_EVT_IN_FIFO_EMPTY_CH2_ST_CLR — Configures whether or not to clear PDMA_AXI_evt_in_fifo_empty_ch2 trigger status.\\0: Invalid, No effect\\1: Clear
  [29] PDMA_AXI_EVT_IN_FIFO_EMPTY_CH1_ST_CLR — Configures whether or not to clear PDMA_AXI_evt_in_fifo_empty_ch1 trigger status.\\0: Invalid, No effect\\1: Clear
  [28] PDMA_AXI_EVT_IN_FIFO_EMPTY_CH0_ST_CLR — Configures whether or not to clear PDMA_AXI_evt_in_fifo_empty_ch0 trigger status.\\0: Invalid, No effect\\1: Clear
  [27] PDMA_AXI_EVT_IN_SUC_EOF_CH2_ST_CLR — Configures whether or not to clear PDMA_AXI_evt_in_suc_eof_ch2 trigger status.\\0: Invalid, No effect\\1: Clear
  [26] PDMA_AXI_EVT_IN_SUC_EOF_CH1_ST_CLR — Configures whether or not to clear PDMA_AXI_evt_in_suc_eof_ch1 trigger status.\\0: Invalid, No effect\\1: Clear
  [25] PDMA_AXI_EVT_IN_SUC_EOF_CH0_ST_CLR — Configures whether or not to clear PDMA_AXI_evt_in_suc_eof_ch0 trigger status.\\0: Invalid, No effect\\1: Clear
  [24] PDMA_AXI_EVT_IN_DONE_CH2_ST_CLR — Configures whether or not to clear PDMA_AXI_evt_in_done_ch2 trigger status.\\0: Invalid, No effect\\1: Clear
  [23] PDMA_AXI_EVT_IN_DONE_CH1_ST_CLR — Configures whether or not to clear PDMA_AXI_evt_in_done_ch1 trigger status.\\0: Invalid, No effect\\1: Clear
  [22] PDMA_AXI_EVT_IN_DONE_CH0_ST_CLR — Configures whether or not to clear PDMA_AXI_evt_in_done_ch0 trigger status.\\0: Invalid, No effect\\1: Clear
  [21] LP_PDMA_AHB_EVT_OUT_FIFO_FULL_CH1_ST_CLR — Configures whether or not to clear LP_PDMA_AHB_evt_out_fifo_full_ch1 trigger status.\\0: Invalid, No effect\\1: Clear
  [20] LP_PDMA_AHB_EVT_OUT_FIFO_FULL_CH0_ST_CLR — Configures whether or not to clear LP_PDMA_AHB_evt_out_fifo_full_ch0 trigger status.\\0: Invalid, No effect\\1: Clear
  [19] LP_PDMA_AHB_EVT_OUT_FIFO_EMPTY_CH1_ST_CLR — Configures whether or not to clear LP_PDMA_AHB_evt_out_fifo_empty_ch1 trigger status.\\0: Invalid, No effect\\1: Clear
  [18] LP_PDMA_AHB_EVT_OUT_FIFO_EMPTY_CH0_ST_CLR — Configures whether or not to clear LP_PDMA_AHB_evt_out_fifo_empty_ch0 trigger status.\\0: Invalid, No effect\\1: Clear
  [17] LP_PDMA_AHB_EVT_OUT_TOTAL_EOF_CH1_ST_CLR — Configures whether or not to clear LP_PDMA_AHB_evt_out_total_eof_ch1 trigger status.\\0: Invalid, No effect\\1: Clear
  [16] LP_PDMA_AHB_EVT_OUT_TOTAL_EOF_CH0_ST_CLR — Configures whether or not to clear LP_PDMA_AHB_evt_out_total_eof_ch0 trigger status.\\0: Invalid, No effect\\1: Clear
  [15] LP_PDMA_AHB_EVT_OUT_EOF_CH1_ST_CLR — Configures whether or not to clear LP_PDMA_AHB_evt_out_eof_ch1 trigger status.\\0: Invalid, No effect\\1: Clear
  [14] LP_PDMA_AHB_EVT_OUT_EOF_CH0_ST_CLR — Configures whether or not to clear LP_PDMA_AHB_evt_out_eof_ch0 trigger status.\\0: Invalid, No effect\\1: Clear
  [13] LP_PDMA_AHB_EVT_OUT_DONE_CH1_ST_CLR — Configures whether or not to clear LP_PDMA_AHB_evt_out_done_ch1 trigger status.\\0: Invalid, No effect\\1: Clear
  [12] LP_PDMA_AHB_EVT_OUT_DONE_CH0_ST_CLR — Configures whether or not to clear LP_PDMA_AHB_evt_out_done_ch0 trigger status.\\0: Invalid, No effect\\1: Clear
  [11] LP_PDMA_AHB_EVT_IN_FIFO_FULL_CH1_ST_CLR — Configures whether or not to clear LP_PDMA_AHB_evt_in_fifo_full_ch1 trigger status.\\0: Invalid, No effect\\1: Clear
  [10] LP_PDMA_AHB_EVT_IN_FIFO_FULL_CH0_ST_CLR — Configures whether or not to clear LP_PDMA_AHB_evt_in_fifo_full_ch0 trigger status.\\0: Invalid, No effect\\1: Clear
  [9] LP_PDMA_AHB_EVT_IN_FIFO_EMPTY_CH1_ST_CLR — Configures whether or not to clear LP_PDMA_AHB_evt_in_fifo_empty_ch1 trigger status.\\0: Invalid, No effect\\1: Clear
  [8] LP_PDMA_AHB_EVT_IN_FIFO_EMPTY_CH0_ST_CLR — Configures whether or not to clear LP_PDMA_AHB_evt_in_fifo_empty_ch0 trigger status.\\0: Invalid, No effect\\1: Clear
  [7] LP_PDMA_AHB_EVT_IN_SUC_EOF_CH1_ST_CLR — Configures whether or not to clear LP_PDMA_AHB_evt_in_suc_eof_ch1 trigger status.\\0: Invalid, No effect\\1: Clear
  [6] LP_PDMA_AHB_EVT_IN_SUC_EOF_CH0_ST_CLR — Configures whether or not to clear LP_PDMA_AHB_evt_in_suc_eof_ch0 trigger status.\\0: Invalid, No effect\\1: Clear
  [5] LP_PDMA_AHB_EVT_IN_DONE_CH1_ST_CLR — Configures whether or not to clear LP_PDMA_AHB_evt_in_done_ch1 trigger status.\\0: Invalid, No effect\\1: Clear
  [4] LP_PDMA_AHB_EVT_IN_DONE_CH0_ST_CLR — Configures whether or not to clear LP_PDMA_AHB_evt_in_done_ch0 trigger status.\\0: Invalid, No effect\\1: Clear
  [n-1] PDMA_AHB_EVT_OUT_FIFO_FULL_CH{n}_ST_CLR (n=1..4) — Configures whether or not to clear PDMA_AHB_evt_out_fifo_full_ch{n} trigger status.\\0: Invalid, No effect\\1: Clear
